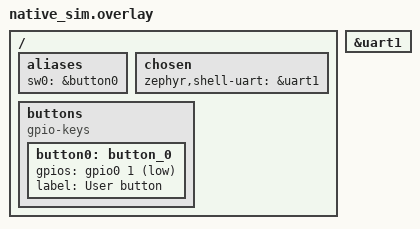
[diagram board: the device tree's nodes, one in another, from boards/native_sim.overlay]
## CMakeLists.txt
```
cmake_minimum_required(VERSION 3.20.0)

include(${CMAKE_CURRENT_SOURCE_DIR}/../cmake/workshop_board.cmake)
find_package(Zephyr REQUIRED HINTS $ENV{ZEPHYR_BASE})
project(app_test)

zephyr_include_directories(src/common)

target_sources(app PRIVATE src/main.c)
add_subdirectory(src/common common)

if(CONFIG_APP_TEST_BUTTON)
  add_subdirectory(src/modules/button button)
endif()

if(CONFIG_APP_TEST_SENSOR)
  add_subdirectory(src/modules/sensor sensor)
endif()

if(CONFIG_APP_TEST_LED)
  add_subdirectory(src/modules/led led)
endif()
```

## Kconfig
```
menu "Test application"

rsource "src/modules/button/Kconfig.button"
rsource "src/modules/sensor/Kconfig.sensor"
rsource "src/modules/led/Kconfig.led"

endmenu

menu "Zephyr Kernel"
source "Kconfig.zephyr"
endmenu
```

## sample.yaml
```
sample:
  description: Application
  name: app
common:
  tags: introduction
tests:
  # Main application with all components
  basic.app:
    tags: introduction
    integration_platforms:
      - native_sim
      - reel_board
    harness: console
    harness_config:
      type: one_line
      regex:
        - "System booted"

  # Component-specific tests using Kconfig options
  # Tests each component in isolation with console harness

  app.test.button:
    extra_args: EXTRA_CONF_FILE=test_cfg/button_component.conf
    integration_platforms:
      - native_sim
      - reel_board
    tags: button
    harness: console
    harness_config:
      type: one_line
      regex:
        - "Button component started"

  app.test.led:
    extra_args: EXTRA_CONF_FILE=test_cfg/led_component.conf
    integration_platforms:
      - native_sim
      - reel_board
    tags: led
    harness: console
    harness_config:
      type: one_line
      regex:
        - "LED component initialized"

  app.test.sys_ctrl:
    extra_args: EXTRA_CONF_FILE=test_cfg/sys_ctrl_component.conf
    integration_platforms:
      - native_sim
    tags: sys_ctrl
    harness: console
    harness_config:
      type: one_line
      regex:
        - "System booted"

  # Build tests for tracing configurations
  app.tracing.native_ctf:
    build_only: true
    extra_args: EXTRA_CONF_FILE=prj_native_ctf.conf
    platform_allow:
      - native_sim
    integration_platforms:
      - native_sim
    tags: tracing

  app.tracing.usb_ctf:
    build_only: true
    extra_args: EXTRA_CONF_FILE=prj_usb_ctf.conf
    platform_allow:
      - nrf52840dk/nrf52840
    integration_platforms:
      - nrf52840dk/nrf52840
    depends_on: usb_device
    tags: tracing

  app.tracing.sysview_rtt:
    build_only: true
    extra_args: EXTRA_CONF_FILE=prj_sysview_rtt.conf
    platform_allow:
      - nrf52840dk/nrf52840
    integration_platforms:
      - nrf52840dk/nrf52840
    filter: CONFIG_HAS_SEGGER_RTT
    tags: tracing
```

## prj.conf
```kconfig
CONFIG_LOG=y
# Flush the deferred log promptly so traces follow the event that caused them.
CONFIG_LOG_PROCESS_THREAD_SLEEP_MS=10
CONFIG_APP_TEST_BUTTON_LOG_LEVEL_DBG=y
CONFIG_APP_TEST_SENSOR_LOG_LEVEL_DBG=y
CONFIG_APP_TEST_LED_LOG_LEVEL_DBG=y

CONFIG_APP_TEST_BUTTON=y
CONFIG_APP_TEST_SENSOR=y
CONFIG_APP_TEST_LED=y

CONFIG_GPIO=y
CONFIG_I2C=y
CONFIG_SENSOR=y
CONFIG_ZBUS=y
CONFIG_ZBUS_MSG_SUBSCRIBER=y
CONFIG_ZBUS_MSG_SUBSCRIBER_BUF_ALLOC_STATIC=y
CONFIG_ZBUS_MSG_SUBSCRIBER_NET_BUF_STATIC_DATA_SIZE=32
CONFIG_ZBUS_MSG_SUBSCRIBER_NET_BUF_POOL_SIZE=16

CONFIG_SHELL=y
```

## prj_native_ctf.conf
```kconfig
# CTF Tracing on native_sim (POSIX backend)
CONFIG_TRACING=y
CONFIG_TRACING_CTF=y
CONFIG_TRACING_SYNC=y
CONFIG_TRACING_BACKEND_POSIX=y
CONFIG_TRACING_PACKET_MAX_SIZE=64

# Trace events
CONFIG_TRACING_THREAD=y
CONFIG_TRACING_ISR=y
CONFIG_TRACING_SEMAPHORE=y
CONFIG_TRACING_MUTEX=y
CONFIG_TRACING_WORK=y
CONFIG_TRACING_SYSCALL=y

# Thread names in trace output
CONFIG_THREAD_NAME=y
CONFIG_DEBUG_THREAD_INFO=y
```

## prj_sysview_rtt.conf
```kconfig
# SEGGER SystemView via RTT (for hardware boards like nrf52840dk)

# Disable components that require specific hardware
CONFIG_TEMPSENSE_COMPONENT=n
CONFIG_TEMP_ALERT_COMPONENT=n

CONFIG_TRACING=y
CONFIG_SEGGER_SYSTEMVIEW=y

# Trace events
CONFIG_TRACING_THREAD=y
CONFIG_TRACING_ISR=y
CONFIG_TRACING_SEMAPHORE=y
CONFIG_TRACING_MUTEX=y
CONFIG_TRACING_WORK=y
CONFIG_TRACING_SYSCALL=y

# Thread names in trace output
CONFIG_THREAD_NAME=y
CONFIG_DEBUG_THREAD_INFO=y
```

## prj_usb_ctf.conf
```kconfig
# CTF Tracing via USB (for hardware boards like nrf52840dk)
CONFIG_GPIO=y

# Disable components that require specific hardware
CONFIG_TEMPSENSE_COMPONENT=n
CONFIG_TEMP_ALERT_COMPONENT=n

# USB Tracing Component - enables USB_DEVICE_STACK_NEXT automatically
CONFIG_TRACING_USB_COMPONENT=y
CONFIG_CDC_ACM_SERIAL_INITIALIZE_AT_BOOT=n

CONFIG_TRACING=y
CONFIG_TRACING_CTF=y
CONFIG_TRACING_ASYNC=y
CONFIG_TRACING_BACKEND_USB=y
CONFIG_TRACING_HANDLE_HOST_CMD=y
CONFIG_TRACING_BUFFER_SIZE=4096

# Trace events
CONFIG_TRACING_THREAD=y
CONFIG_TRACING_ISR=y
CONFIG_TRACING_SEMAPHORE=y
CONFIG_TRACING_MUTEX=y
CONFIG_TRACING_WORK=y
CONFIG_TRACING_SYSCALL=y

# Thread names in trace output
CONFIG_THREAD_NAME=y
CONFIG_DEBUG_THREAD_INFO=y
```

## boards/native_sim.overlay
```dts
/**
 * Native Sim Overlay for Application
 *
 * This overlay adds a button (sw0) aliases for the native_sim board to enable
 * the button module to compile and run. Also enables uart1 for shell on
 * separate console.
 */

/ {
	aliases {
		sw0 = &button0;
	};

	chosen {
		zephyr,shell-uart = &uart1;
	};

	buttons {
		compatible = "gpio-keys";
		button0: button_0 {
			gpios = <&gpio0 1 GPIO_ACTIVE_LOW>;
			label = "User button";
		};
	};
};

&uart1 {
	status = "okay";
};
```

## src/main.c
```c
/*
 * Copyright (c) 2026 Jonas Remmert
 * SPDX-License-Identifier: Apache-2.0
 */

#include <zephyr/logging/log.h>

LOG_MODULE_REGISTER(app_test, LOG_LEVEL_INF);

int main(void)
{
	LOG_INF("App test booted");
	return 0;
}
```

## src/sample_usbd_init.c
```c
/*
 * Copyright (c) 2023 Nordic Semiconductor ASA
 *
 * SPDX-License-Identifier: Apache-2.0
 */

#include <stdint.h>

#include <zephyr/device.h>
#include <zephyr/usb/usbd.h>
#include <zephyr/usb/bos.h>

#include <zephyr/logging/log.h>
LOG_MODULE_REGISTER(usbd_sample_config);

/* Default USB device configuration values */
#ifndef CONFIG_SAMPLE_USBD_VID
#define CONFIG_SAMPLE_USBD_VID 0x2fe3
#endif

#ifndef CONFIG_SAMPLE_USBD_PID
#define CONFIG_SAMPLE_USBD_PID 0x0001
#endif

#ifndef CONFIG_SAMPLE_USBD_MANUFACTURER
#define CONFIG_SAMPLE_USBD_MANUFACTURER "Zephyr Project"
#endif

#ifndef CONFIG_SAMPLE_USBD_PRODUCT
#define CONFIG_SAMPLE_USBD_PRODUCT "Zephyr Tracing Device"
#endif

#ifndef CONFIG_SAMPLE_USBD_MAX_POWER
#define CONFIG_SAMPLE_USBD_MAX_POWER 125
#endif

#ifndef CONFIG_SAMPLE_USBD_SELF_POWERED
#define CONFIG_SAMPLE_USBD_SELF_POWERED 1
#endif

#ifndef CONFIG_SAMPLE_USBD_REMOTE_WAKEUP
#define CONFIG_SAMPLE_USBD_REMOTE_WAKEUP 0
#endif

/* By default, do not register the USB DFU class DFU mode instance. */
static const char *const blocklist[] = {
	"dfu_dfu",
	NULL,
};

/* doc device instantiation start */
/*
 * Instantiate a context named sample_usbd using the default USB device
 * controller, the Zephyr project vendor ID, and the sample product ID.
 * Zephyr project vendor ID must not be used outside of Zephyr samples.
 */
USBD_DEVICE_DEFINE(sample_usbd,
		   DEVICE_DT_GET(DT_NODELABEL(zephyr_udc0)),
		   CONFIG_SAMPLE_USBD_VID, CONFIG_SAMPLE_USBD_PID);
/* doc device instantiation end */

/* doc string instantiation start */
USBD_DESC_LANG_DEFINE(sample_lang);
USBD_DESC_MANUFACTURER_DEFINE(sample_mfr, CONFIG_SAMPLE_USBD_MANUFACTURER);
USBD_DESC_PRODUCT_DEFINE(sample_product, CONFIG_SAMPLE_USBD_PRODUCT);
IF_ENABLED(CONFIG_HWINFO, (USBD_DESC_SERIAL_NUMBER_DEFINE(sample_sn)));

/* doc string instantiation end */

USBD_DESC_CONFIG_DEFINE(fs_cfg_desc, "FS Configuration");
USBD_DESC_CONFIG_DEFINE(hs_cfg_desc, "HS Configuration");

/* doc configuration instantiation start */
static const uint8_t attributes = (IS_ENABLED(CONFIG_SAMPLE_USBD_SELF_POWERED) ?
				   USB_SCD_SELF_POWERED : 0) |
				  (IS_ENABLED(CONFIG_SAMPLE_USBD_REMOTE_WAKEUP) ?
				   USB_SCD_REMOTE_WAKEUP : 0);

/* Full speed configuration */
USBD_CONFIGURATION_DEFINE(sample_fs_config,
			  attributes,
			  CONFIG_SAMPLE_USBD_MAX_POWER, &fs_cfg_desc);

/* High speed configuration */
USBD_CONFIGURATION_DEFINE(sample_hs_config,
			  attributes,
			  CONFIG_SAMPLE_USBD_MAX_POWER, &hs_cfg_desc);
/* doc configuration instantiation end */

#if CONFIG_SAMPLE_USBD_20_EXTENSION_DESC
/*
 * This does not yet provide valuable information, but rather serves as an
 * example, and will be improved in the future.
 */
static const struct usb_bos_capability_lpm bos_cap_lpm = {
	.bLength = sizeof(struct usb_bos_capability_lpm),
	.bDescriptorType = USB_DESC_DEVICE_CAPABILITY,
	.bDevCapabilityType = USB_BOS_CAPABILITY_EXTENSION,
	.bmAttributes = 0UL,
};

USBD_DESC_BOS_DEFINE(sample_usbext, sizeof(bos_cap_lpm), &bos_cap_lpm);
#endif

static void sample_fix_code_triple(struct usbd_context *uds_ctx,
				   const enum usbd_speed speed)
{
	/* Always use class code information from Interface Descriptors */
	if (IS_ENABLED(CONFIG_USBD_CDC_ACM_CLASS) ||
	    IS_ENABLED(CONFIG_USBD_CDC_ECM_CLASS) ||
	    IS_ENABLED(CONFIG_USBD_CDC_NCM_CLASS) ||
	    IS_ENABLED(CONFIG_USBD_MIDI2_CLASS) ||
	    IS_ENABLED(CONFIG_USBD_AUDIO2_CLASS) ||
	    IS_ENABLED(CONFIG_USBD_VIDEO_CLASS)) {
		/*
		 * Class with multiple interfaces have an Interface
		 * Association Descriptor available, use an appropriate triple
		 * to indicate it.
		 */
		usbd_device_set_code_triple(uds_ctx, speed,
					    USB_BCC_MISCELLANEOUS, 0x02, 0x01);
	} else {
		usbd_device_set_code_triple(uds_ctx, speed, 0, 0, 0);
	}
}

struct usbd_context *sample_usbd_setup_device(usbd_msg_cb_t msg_cb)
{
	int err;

	/* doc add string descriptor start */
	err = usbd_add_descriptor(&sample_usbd, &sample_lang);
	if (err) {
		LOG_ERR("Failed to initialize language descriptor (%d)", err);
		return NULL;
	}

	err = usbd_add_descriptor(&sample_usbd, &sample_mfr);
	if (err) {
		LOG_ERR("Failed to initialize manufacturer descriptor (%d)", err);
		return NULL;
	}

	err = usbd_add_descriptor(&sample_usbd, &sample_product);
	if (err) {
		LOG_ERR("Failed to initialize product descriptor (%d)", err);
		return NULL;
	}

	IF_ENABLED(CONFIG_HWINFO, (
		err = usbd_add_descriptor(&sample_usbd, &sample_sn);
	))
	if (err) {
		LOG_ERR("Failed to initialize SN descriptor (%d)", err);
		return NULL;
	}
	/* doc add string descriptor end */

	if (USBD_SUPPORTS_HIGH_SPEED &&
	    usbd_caps_speed(&sample_usbd) == USBD_SPEED_HS) {
		err = usbd_add_configuration(&sample_usbd, USBD_SPEED_HS,
					     &sample_hs_config);
		if (err) {
			LOG_ERR("Failed to add High-Speed configuration");
			return NULL;
		}

		err = usbd_register_all_classes(&sample_usbd, USBD_SPEED_HS, 1,
						blocklist);
		if (err) {
			LOG_ERR("Failed to add register classes");
			return NULL;
		}

		sample_fix_code_triple(&sample_usbd, USBD_SPEED_HS);
	}

	/* doc configuration register start */
	err = usbd_add_configuration(&sample_usbd, USBD_SPEED_FS,
				     &sample_fs_config);
	if (err) {
		LOG_ERR("Failed to add Full-Speed configuration");
		return NULL;
	}
	/* doc configuration register end */

	/* doc functions register start */
	err = usbd_register_all_classes(&sample_usbd, USBD_SPEED_FS, 1, blocklist);
	if (err) {
		LOG_ERR("Failed to add register classes");
		return NULL;
	}
	/* doc functions register end */

	sample_fix_code_triple(&sample_usbd, USBD_SPEED_FS);
	usbd_self_powered(&sample_usbd, attributes & USB_SCD_SELF_POWERED);

	if (msg_cb != NULL) {
		/* doc device init-and-msg start */
		err = usbd_msg_register_cb(&sample_usbd, msg_cb);
		if (err) {
			LOG_ERR("Failed to register message callback");
			return NULL;
		}
		/* doc device init-and-msg end */
	}

#if CONFIG_SAMPLE_USBD_20_EXTENSION_DESC
	(void)usbd_device_set_bcd_usb(&sample_usbd, USBD_SPEED_FS, 0x0201);
	(void)usbd_device_set_bcd_usb(&sample_usbd, USBD_SPEED_HS, 0x0201);

	err = usbd_add_descriptor(&sample_usbd, &sample_usbext);
	if (err) {
		LOG_ERR("Failed to add USB 2.0 Extension Descriptor");
		return NULL;
	}
#endif

	return &sample_usbd;
}

struct usbd_context *sample_usbd_init_device(usbd_msg_cb_t msg_cb)
{
	int err;

	if (sample_usbd_setup_device(msg_cb) == NULL) {
		return NULL;
	}

	/* doc device init start */
	err = usbd_init(&sample_usbd);
	if (err) {
		LOG_ERR("Failed to initialize device support");
		return NULL;
	}
	/* doc device init end */

	return &sample_usbd;
}
```
